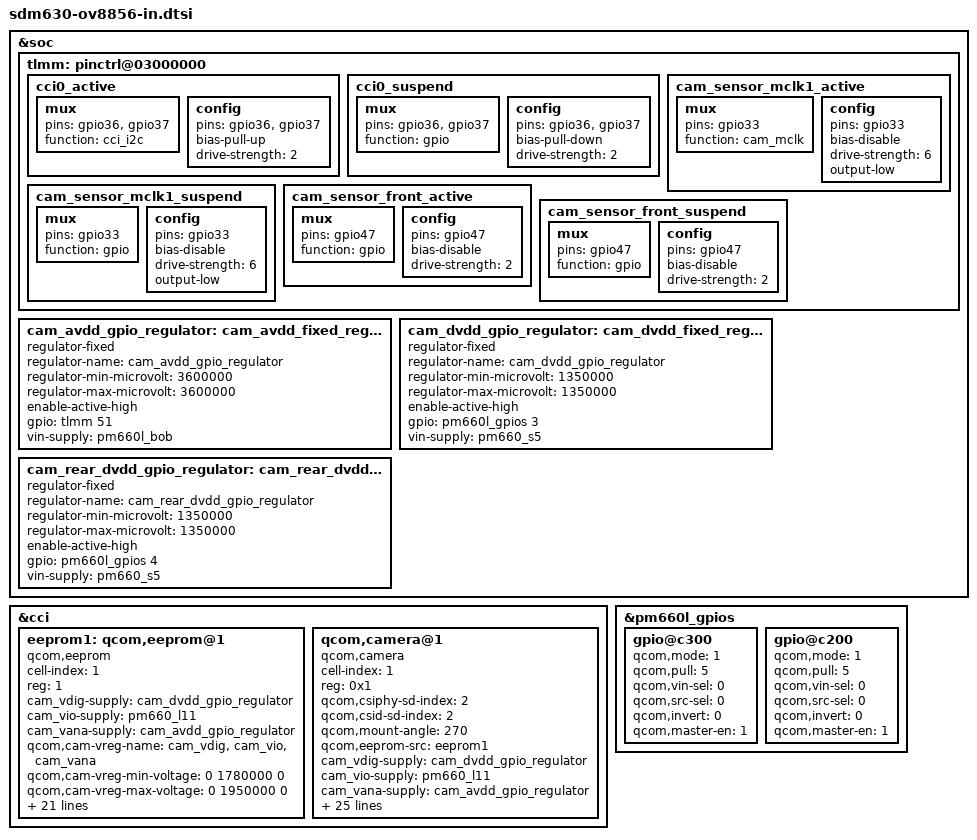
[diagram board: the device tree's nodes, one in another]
/*
 * This software is contributed or developed by KYOCERA Corporation.
 * (C) 2018 KYOCERA Corporation
 *
 * This program is free software; you can redistribute it and/or modify
 * it under the terms of the GNU General Public License version 2 and
 * only version 2 as published by the Free Software Foundation.
 *
 * This program is distributed in the hope that it will be useful,
 * but WITHOUT ANY WARRANTY; without even the implied warranty of
 * MERCHANTABILITY or FITNESS FOR A PARTICULAR PURPOSE.  See the
 * GNU General Public License for more details.
 */


&soc {
	tlmm: pinctrl@03000000 {
		cci0_active: cci0_active {
			mux {
				/* CLK, DATA */
				pins = "gpio36","gpio37"; // Only 2
				function = "cci_i2c";
			};

			config {
				pins = "gpio36","gpio37";
				bias-pull-up; /* PULL UP*/
				drive-strength = <2>; /* 2 MA */
			};
		};

		cci0_suspend: cci0_suspend {
			mux {
				/* CLK, DATA */
				pins = "gpio36","gpio37";
				function = "gpio";
			};

			config {
				pins = "gpio36","gpio37";
				bias-pull-down; /* PULL DOWN */
				drive-strength = <2>; /* 2 MA */
			};
		};

		cam_sensor_mclk1_active: cam_sensor_mclk1_active {
			/* MCLK1 */
			mux {
				/* CLK */
				pins = "gpio33";
				function = "cam_mclk";
			};

			config {
				pins = "gpio33";
				bias-disable; /* No PULL */
				drive-strength = <6>; /* 6 MA */
				output-low;
			};
		};

		cam_sensor_mclk1_suspend: cam_sensor_mclk1_suspend {
			/* MCLK1 */
			mux {
				/* CLK */
				pins = "gpio33";
				function = "gpio";
			};

			config {
				pins = "gpio33";
				bias-disable; /* No PULL */
				drive-strength = <6>; /* 6 MA */
				output-low;
			};
		};

		cam_sensor_front_active: cam_sensor_front_active {
			/* RESET */
			mux {
				pins = "gpio47";
				function = "gpio";
			};

			config {
				pins = "gpio47";
				bias-disable; /* No PULL */
				drive-strength = <2>; /* 2 MA */
			};
		};

		cam_sensor_front_suspend: cam_sensor_front_suspend {
			/* RESET */
			mux {
				pins = "gpio47";
				function = "gpio";
			};

			config {
				pins = "gpio47";
				bias-disable; /* No PULL */
				drive-strength = <2>; /* 2 MA */
			};
		};
	};
};

&soc {
	cam_avdd_gpio_regulator: cam_avdd_fixed_regulator {
		compatible = "regulator-fixed";
		regulator-name = "cam_avdd_gpio_regulator";
		regulator-min-microvolt = <3600000>;
		regulator-max-microvolt = <3600000>;
		enable-active-high;
		gpio = <&tlmm 51 0>;
		vin-supply = <&pm660l_bob>;
	};

	cam_dvdd_gpio_regulator: cam_dvdd_fixed_regulator {
		compatible = "regulator-fixed";
		regulator-name = "cam_dvdd_gpio_regulator";
		regulator-min-microvolt = <1350000>;
		regulator-max-microvolt = <1350000>;
		enable-active-high;
		gpio = <&pm660l_gpios 3 0>;
		vin-supply = <&pm660_s5>;
	};

	cam_rear_dvdd_gpio_regulator: cam_rear_dvdd_fixed_regulator {
		compatible = "regulator-fixed";
		regulator-name = "cam_rear_dvdd_gpio_regulator";
		regulator-min-microvolt = <1350000>;
		regulator-max-microvolt = <1350000>;
		enable-active-high;
		gpio = <&pm660l_gpios 4 0>;
		vin-supply = <&pm660_s5>;
	};
};

&cci {
	eeprom1: qcom,eeprom@1 {
		cell-index = <1>;
		reg = <1>;
		compatible = "qcom,eeprom";
		cam_vdig-supply = <&cam_dvdd_gpio_regulator>;
		cam_vio-supply = <&pm660_l11>;
		cam_vana-supply = <&cam_avdd_gpio_regulator>;
		qcom,cam-vreg-name = "cam_vdig", "cam_vio", "cam_vana";
		qcom,cam-vreg-min-voltage = <0 1780000 0>;
		qcom,cam-vreg-max-voltage = <0 1950000 0>;
		qcom,cam-vreg-op-mode = <0 105000 0>;
		qcom,gpio-no-mux = <0>;
		pinctrl-names = "cam_default", "cam_suspend";
		pinctrl-0 = <&cam_sensor_mclk1_active
				&cam_sensor_front_active>;
		pinctrl-1 = <&cam_sensor_mclk1_suspend
				&cam_sensor_front_suspend>;
		gpios = <&tlmm 33 0>,
			<&tlmm 51 0>,
			<&pm660l_gpios 3 0>,
			<&tlmm 47 0>;
		qcom,gpio-vana = <1>;
		qcom,gpio-vdig = <2>;
		qcom,gpio-reset = <3>;
		qcom,gpio-req-tbl-num = <0 1 2 3>;
		qcom,gpio-req-tbl-flags = <1 0 0 0>;
		qcom,gpio-req-tbl-label = "CAMIF_MCLK1", "CAM_VANA", "CAM_VDIG", "CAM_RESET1";
		qcom,sensor-position = <1>;
		qcom,sensor-mode = <0>;
		qcom,cci-master = <0>;
		status = "ok";
		clocks = <&clock_mmss MCLK1_CLK_SRC>,
			<&clock_mmss MMSS_CAMSS_MCLK1_CLK>;
		clock-names = "cam_src_clk", "cam_clk";
		qcom,clock-rates = <24000000 0>;
	};

	qcom,camera@1 {
		cell-index = <1>;
		compatible = "qcom,camera";
		reg = <0x1>;
		qcom,csiphy-sd-index = <2>;
		qcom,csid-sd-index = <2>;
		qcom,mount-angle = <270>;
		qcom,eeprom-src = <&eeprom1>;
		cam_vdig-supply = <&cam_dvdd_gpio_regulator>;
		cam_vio-supply = <&pm660_l11>;
		cam_vana-supply = <&cam_avdd_gpio_regulator>;
		qcom,cam-vreg-name = "cam_vdig", "cam_vio", "cam_vana";
		qcom,cam-vreg-min-voltage = <0 1780000 0>;
		qcom,cam-vreg-max-voltage = <0 1950000 0>;
		qcom,cam-vreg-op-mode = <0 105000 0>;
		qcom,gpio-no-mux = <0>;
		pinctrl-names = "cam_default", "cam_suspend";
		pinctrl-0 = <&cam_sensor_mclk1_active
				 &cam_sensor_front_active>;
		pinctrl-1 = <&cam_sensor_mclk1_suspend
				 &cam_sensor_front_suspend>;
		gpios = <&tlmm 33 0>,
			<&tlmm 51 0>,
			<&pm660l_gpios 3 0>,
			<&tlmm 47 0>;
		qcom,gpio-vana = <1>;
		qcom,gpio-vdig = <2>;
		qcom,gpio-reset = <3>;
		qcom,gpio-req-tbl-num = <0 1 2 3>;
		qcom,gpio-req-tbl-flags = <1 0 0 0>;
		qcom,gpio-req-tbl-label = "CAMIF_MCLK1", "CAM_VANA", "CAM_VDIG", "CAM_RESET1";
		qcom,sensor-position = <1>;
		qcom,sensor-mode = <0>;
		qcom,cci-master = <0>;
		status = "ok";
		clocks = <&clock_mmss MCLK1_CLK_SRC>,
			<&clock_mmss MMSS_CAMSS_MCLK1_CLK>;
		clock-names = "cam_src_clk", "cam_clk";
		qcom,clock-rates = <24000000 0>;
	};
};

&pm660l_gpios {
	gpio@c300 { /* GPIO4 -CAMERA SENSOR 0 VDIG*/
		qcom,mode = <1>;                /* Output */
		qcom,pull = <5>;                /* No Pull */
		qcom,vin-sel = <0>;             /* VIN1 GPIO_LV */
		qcom,src-sel = <0>;             /* GPIO */
		qcom,invert = <0>;              /* Invert */
		qcom,master-en = <1>;           /* Enable GPIO */
		status = "ok";
	};

	gpio@c200 { /* GPIO3 -CAMERA SENSOR 2 VDIG*/
		qcom,mode = <1>;                /* Output */
		qcom,pull = <5>;                /* No Pull */
		qcom,vin-sel = <0>;             /* VIN1 GPIO_LV */
		qcom,src-sel = <0>;             /* GPIO */
		qcom,invert = <0>;              /* Invert */
		qcom,master-en = <1>;           /* Enable GPIO */
		status = "ok";
	};
};
